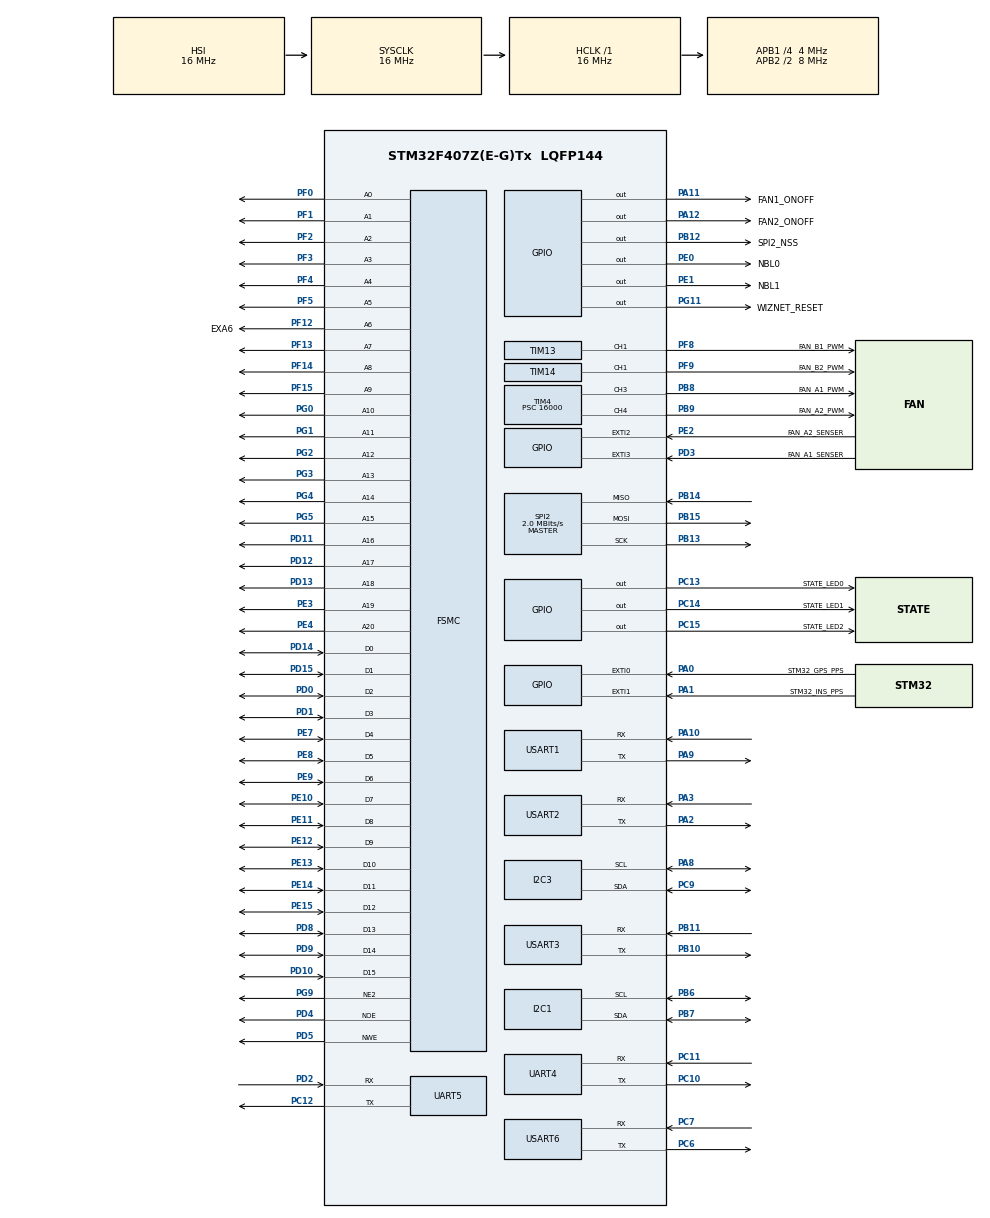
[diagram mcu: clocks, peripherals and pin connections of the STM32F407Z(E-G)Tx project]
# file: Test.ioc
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FSMC.AddressSetupTime2=0
FSMC.BusTurnAroundDuration2=0
FSMC.DataSetupTime2=3
FSMC.WriteOperation2=FSMC_WRITE_OPERATION_ENABLE
Mcu.Family=STM32F4
Mcu.Name=STM32F407Z(E-G)Tx
Mcu.Package=LQFP144
NVIC.PriorityGroup=NVIC_PRIORITYGROUP_4
NVIC.USART2_IRQn=true\:0\:0\:false\:false\:true\:true\:true\:true
PA0-WKUP.GPIO_Label=STM32_GPS_PPS
PA0-WKUP.Signal=GPXTI0
PA1.GPIO_Label=STM32_INS_PPS
PA1.Signal=GPXTI1
PA10.Mode=Asynchronous
PA10.Signal=USART1_RX
PA11.GPIO_Label=FAN1_ONOFF
PA11.Signal=GPIO_Output
PA12.GPIO_Label=FAN2_ONOFF
PA12.Signal=GPIO_Output
PA13.Mode=JTAG_5_pins
PA13.Signal=SYS_JTMS-SWDIO
PA14.Mode=JTAG_5_pins
PA14.Signal=SYS_JTCK-SWCLK
PA15.Mode=JTAG_5_pins
PA15.Signal=SYS_JTDI
PA2.Mode=Asynchronous
PA2.Signal=USART2_TX
PA3.Mode=Asynchronous
PA3.Signal=USART2_RX
PA8.GPIO_Pu=GPIO_PULLUP
PA8.Mode=I2C
PA8.Signal=I2C3_SCL
PA9.Mode=Asynchronous
PA9.Signal=USART1_TX
PB10.Mode=Asynchronous
PB10.Signal=USART3_TX
PB11.Mode=Asynchronous
PB11.Signal=USART3_RX
PB12.GPIO_Label=SPI2_NSS
PB12.Signal=GPIO_Output
PB13.Mode=Full_Duplex_Master
PB13.Signal=SPI2_SCK
PB14.Mode=Full_Duplex_Master
PB14.Signal=SPI2_MISO
PB15.Mode=Full_Duplex_Master
PB15.Signal=SPI2_MOSI
PB3.Mode=JTAG_5_pins
PB3.Signal=SYS_JTDO-SWO
PB4.Mode=JTAG_5_pins
PB4.Signal=SYS_JTRST
PB6.GPIO_Pu=GPIO_PULLUP
PB6.Mode=I2C
PB6.Signal=I2C1_SCL
PB7.GPIO_Pu=GPIO_PULLUP
PB7.Mode=I2C
PB7.Signal=I2C1_SDA
PB8.GPIO_Label=FAN_A1_PWM
PB8.Signal=S_TIM4_CH3
PB9.GPIO_Label=FAN_A2_PWM
PB9.Signal=S_TIM4_CH4
PC10.Mode=Asynchronous
PC10.Signal=UART4_TX
PC11.Mode=Asynchronous
PC11.Signal=UART4_RX
PC12.Mode=Asynchronous
PC12.Signal=UART5_TX
PC13-ANTI_TAMP.GPIO_Label=STATE_LED0
PC13-ANTI_TAMP.Signal=GPIO_Output
PC14-OSC32_IN.GPIO_Label=STATE_LED1
PC14-OSC32_IN.Signal=GPIO_Output
PC15-OSC32_OUT.GPIO_Label=STATE_LED2
PC15-OSC32_OUT.Signal=GPIO_Output
PC6.Mode=Asynchronous
PC6.Signal=USART6_TX
PC7.Mode=Asynchronous
PC7.Signal=USART6_RX
PC9.GPIO_Pu=GPIO_PULLUP
PC9.Mode=I2C
PC9.Signal=I2C3_SDA
PD0.Signal=FSMC_D2_DA2
PD1.Signal=FSMC_D3_DA3
PD10.Signal=FSMC_D15_DA15
PD11.Signal=FSMC_A16_CLE
PD12.Signal=FSMC_A17_ALE
PD13.Signal=FSMC_A18
PD14.Signal=FSMC_D0_DA0
PD15.Signal=FSMC_D1_DA1
PD2.Mode=Asynchronous
PD2.Signal=UART5_RX
PD3.GPIO_Label=FAN_A1_SENSER
PD3.Signal=GPXTI3
PD4.Signal=FSMC_NOE
PD5.Signal=FSMC_NWE
PD8.Signal=FSMC_D13_DA13
PD9.Signal=FSMC_D14_DA14
PE0.GPIO_Label=NBL0
PE0.Signal=GPIO_Output
PE1.GPIO_Label=NBL1
PE1.Signal=GPIO_Output
PE10.Signal=FSMC_D7_DA7
PE11.Signal=FSMC_D8_DA8
PE12.Signal=FSMC_D9_DA9
PE13.Signal=FSMC_D10_DA10
PE14.Signal=FSMC_D11_DA11
PE15.Signal=FSMC_D12_DA12
PE2.GPIO_Label=FAN_A2_SENSER
PE2.Signal=GPXTI2
PE3.Signal=FSMC_A19
PE4.Signal=FSMC_A20
PE7.Signal=FSMC_D4_DA4
PE8.Signal=FSMC_D5_DA5
PE9.Signal=FSMC_D6_DA6
PF0.Signal=FSMC_A0
PF1.Signal=FSMC_A1
PF12.GPIO_Label=EXA6
PF12.Signal=FSMC_A6
PF13.Signal=FSMC_A7
PF14.Signal=FSMC_A8
PF15.Signal=FSMC_A9
PF2.Signal=FSMC_A2
PF3.Signal=FSMC_A3
PF4.Signal=FSMC_A4
PF5.Signal=FSMC_A5
PF8.GPIO_Label=FAN_B1_PWM
PF8.Signal=S_TIM13_CH1
PF9.GPIO_Label=FAN_B2_PWM
PF9.Signal=S_TIM14_CH1
PG0.Signal=FSMC_A10
PG1.Signal=FSMC_A11
PG11.GPIO_Label=WIZNET_RESET
PG11.PinState=GPIO_PIN_SET
PG11.Signal=GPIO_Output
PG2.Signal=FSMC_A12
PG3.Signal=FSMC_A13
PG4.Signal=FSMC_A14
PG5.Signal=FSMC_A15
PG9.Mode=NorPsramChipSelect2_2
PG9.Signal=FSMC_NE2
PH0-OSC_IN.Mode=HSE-External-Oscillator
PH0-OSC_IN.Signal=RCC_OSC_IN
PH1-OSC_OUT.Mode=HSE-External-Oscillator
PH1-OSC_OUT.Signal=RCC_OSC_OUT
ProjectManager.HeapSize=0x200
ProjectManager.StackSize=0x400
ProjectManager.TargetToolchain=EWARM V8.32
RCC.48MHZClocksFreq_Value=32000000
RCC.AHBFreq_Value=16000000
RCC.APB1CLKDivider=RCC_HCLK_DIV4
RCC.APB1Freq_Value=4000000
RCC.APB1TimFreq_Value=8000000
RCC.APB2CLKDivider=RCC_HCLK_DIV2
RCC.APB2Freq_Value=8000000
RCC.APB2TimFreq_Value=16000000
RCC.CortexFreq_Value=16000000
RCC.HCLKFreq_Value=16000000
RCC.HSE_VALUE=25000000
RCC.HSI_VALUE=16000000
RCC.LSE_VALUE=32768
RCC.PLLM=8
RCC.PLLN=64
RCC.SYSCLKFreq_VALUE=16000000
RCC.VCOOutputFreq_Value=128000000
SH.FSMC_A0.0=FSMC_A0,21b-a2
SH.FSMC_A1.0=FSMC_A1,21b-a2
SH.FSMC_A10.0=FSMC_A10,21b-a2
SH.FSMC_A11.0=FSMC_A11,21b-a2
SH.FSMC_A12.0=FSMC_A12,21b-a2
SH.FSMC_A13.0=FSMC_A13,21b-a2
SH.FSMC_A14.0=FSMC_A14,21b-a2
SH.FSMC_A15.0=FSMC_A15,21b-a2
SH.FSMC_A16_CLE.0=FSMC_A16,21b-a2
SH.FSMC_A17_ALE.0=FSMC_A17,21b-a2
SH.FSMC_A18.0=FSMC_A18,21b-a2
SH.FSMC_A19.0=FSMC_A19,21b-a2
SH.FSMC_A2.0=FSMC_A2,21b-a2
SH.FSMC_A20.0=FSMC_A20,21b-a2
SH.FSMC_A3.0=FSMC_A3,21b-a2
SH.FSMC_A4.0=FSMC_A4,21b-a2
SH.FSMC_A5.0=FSMC_A5,21b-a2
SH.FSMC_A6.0=FSMC_A6
SH.FSMC_A6.1=FSMC_A6,21b-a2
SH.FSMC_A7.0=FSMC_A7,21b-a2
SH.FSMC_A8.0=FSMC_A8,21b-a2
SH.FSMC_A9.0=FSMC_A9,21b-a2
SH.FSMC_D0_DA0.0=FSMC_D0,16b-d2
SH.FSMC_D10_DA10.0=FSMC_D10,16b-d2
SH.FSMC_D11_DA11.0=FSMC_D11,16b-d2
SH.FSMC_D12_DA12.0=FSMC_D12,16b-d2
SH.FSMC_D13_DA13.0=FSMC_D13,16b-d2
SH.FSMC_D14_DA14.0=FSMC_D14,16b-d2
SH.FSMC_D15_DA15.0=FSMC_D15,16b-d2
SH.FSMC_D1_DA1.0=FSMC_D1,16b-d2
SH.FSMC_D2_DA2.0=FSMC_D2,16b-d2
SH.FSMC_D3_DA3.0=FSMC_D3,16b-d2
SH.FSMC_D4_DA4.0=FSMC_D4,16b-d2
SH.FSMC_D5_DA5.0=FSMC_D5,16b-d2
SH.FSMC_D6_DA6.0=FSMC_D6,16b-d2
SH.FSMC_D7_DA7.0=FSMC_D7,16b-d2
SH.FSMC_D8_DA8.0=FSMC_D8,16b-d2
SH.FSMC_D9_DA9.0=FSMC_D9,16b-d2
SH.FSMC_NOE.0=FSMC_NOE
SH.FSMC_NOE.1=FSMC_NOE,Sram2
SH.FSMC_NWE.0=FSMC_NWE,Sram2
SH.S_TIM13_CH1.0=TIM13_CH1,PWM Generation1 CH1
SH.S_TIM14_CH1.0=TIM14_CH1,PWM Generation1 CH1
SH.S_TIM4_CH3.0=TIM4_CH3,PWM Generation3 CH3
SH.S_TIM4_CH4.0=TIM4_CH4,PWM Generation4 CH4
SPI2.CalculateBaudRate=2.0 MBits/s
SPI2.Direction=SPI_DIRECTION_2LINES
SPI2.Mode=SPI_MODE_MASTER
SPI2.VirtualType=VM_MASTER
TIM13.Channel=TIM_CHANNEL_1
TIM13.Period=500
TIM13.Prescaler=4000
TIM13.Pulse=350
TIM14.Channel=TIM_CHANNEL_1
TIM14.Period=500
TIM14.Prescaler=4000
TIM14.Pulse=350
TIM4.Channel-PWM\ Generation3\ CH3=TIM_CHANNEL_3
TIM4.Channel-PWM\ Generation4\ CH4=TIM_CHANNEL_4
TIM4.Period=1000
TIM4.Prescaler=16000
TIM4.Pulse-PWM\ Generation3\ CH3=100
TIM4.Pulse-PWM\ Generation4\ CH4=100
UART4.VirtualMode=Asynchronous
UART5.VirtualMode=Asynchronous
USART1.VirtualMode=VM_ASYNC
USART2.VirtualMode=VM_ASYNC
USART3.VirtualMode=VM_ASYNC
USART6.VirtualMode=VM_ASYNC
VP_TIM13_VS_ClockSourceINT.Mode=Enable_Timer
VP_TIM14_VS_ClockSourceINT.Mode=Enable_Timer
VP_TIM4_VS_ClockSourceINT.Mode=Internal
board=custom

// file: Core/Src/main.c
/* USER CODE BEGIN Header */
/**
******************************************************************************
* @file           : main.c
* @brief          : Main program body
******************************************************************************
* @attention
*
* Copyright (c) 2022 STMicroelectronics.
* All rights reserved.
*
* This software is licensed under terms that can be found in the LICENSE file
* in the root directory of this software component.
* If no LICENSE file comes with this software, it is provided AS-IS.
*
******************************************************************************
*/
/* USER CODE END Header */
#include "main.h"

/* USER CODE BEGIN Includes */
#include "stdio.h"
#include "wizchip_conf.h"
/* USER CODE END Includes */

I2C_HandleTypeDef hi2c1;
I2C_HandleTypeDef hi2c3;

SPI_HandleTypeDef hspi2;

TIM_HandleTypeDef htim4;
TIM_HandleTypeDef htim13;
TIM_HandleTypeDef htim14;

UART_HandleTypeDef huart4;
UART_HandleTypeDef huart5;
UART_HandleTypeDef huart1;
UART_HandleTypeDef huart2;
UART_HandleTypeDef huart3;
UART_HandleTypeDef huart6;

SRAM_HandleTypeDef hsram2;

void SystemClock_Config(void);
static void MX_GPIO_Init(void);
static void MX_I2C3_Init(void);
static void MX_UART4_Init(void);
static void MX_UART5_Init(void);
static void MX_USART1_UART_Init(void);
static void MX_USART2_UART_Init(void);
static void MX_USART3_UART_Init(void);
static void MX_USART6_UART_Init(void);
static void MX_SPI2_Init(void);
static void MX_I2C1_Init(void);
static void MX_TIM4_Init(void);
static void MX_FSMC_Init(void);
static void MX_TIM13_Init(void);
static void MX_TIM14_Init(void);

/* USER CODE BEGIN 0 */

#define SOCK_OPEN                       0x01
#define SOCK_CLOSE                      0x10
#define SOCK_MR_UDP                     0x02
#define SOCK_NUM_0                      0x00

#define W5300_BANK_ADDR                 ((uint32_t)0x64000000)
#define _W5300_DATA(p)                  (*(volatile unsigned short*) (W5300_BANK_ADDR + (p<<1)))

uint16_t wr_data;
uint16_t rd_data;

int fputc(int ch,  FILE *f){

  HAL_UART_Transmit(&huart2,(uint8_t*)&ch,1,1);

  return ch;

}
wiz_NetInfo gWIZNETINFO = {
  .mac = {0x00, 0x08, 0xdc, 0, 0, 0},
  .ip = {172, 30, 1, 104},
  .sn = {255, 255, 0, 0},
  .gw = {172, 30, 1, 254},
  .dns = {0, 0, 0, 0},
  .dhcp = NETINFO_STATIC
};
uint8_t wiznet_memsize[2][8] = {{8,8,8,8,8,8,8,8}, {8,8,8,8,8,8,8,8}};
#define ETH_MAX_BUF_SIZE		2048
uint8_t ethBuf0[ETH_MAX_BUF_SIZE];

void Reset_W5300()
{
  HAL_GPIO_WritePin(GPIOG, WIZNET_RESET_Pin, GPIO_PIN_RESET);
  HAL_Delay(1);

  HAL_GPIO_WritePin(GPIOG, WIZNET_RESET_Pin, GPIO_PIN_SET);
  HAL_Delay(10);

}

void W5300_write(uint32_t addr, iodata_t wd)
{
  _W5300_DATA(addr) = wd;
}

iodata_t W5300_read(uint32_t addr)
{
  return _W5300_DATA(addr);
}

void print_network_information(void)
{
  wizchip_getnetinfo(&gWIZNETINFO);
  printf("Mac address: %02x:%02x:%02x:%02x:%02x:%02x\r\n",gWIZNETINFO.mac[0],gWIZNETINFO.mac[1],gWIZNETINFO.mac[2],gWIZNETINFO.mac[3],gWIZNETINFO.mac[4],gWIZNETINFO.mac[5]);
  printf("IP address : %d.%d.%d.%d\r\n",gWIZNETINFO.ip[0],gWIZNETINFO.ip[1],gWIZNETINFO.ip[2],gWIZNETINFO.ip[3]);
  printf("SM Mask    : %d.%d.%d.%d\r\n",gWIZNETINFO.sn[0],gWIZNETINFO.sn[1],gWIZNETINFO.sn[2],gWIZNETINFO.sn[3]);
  printf("Gate way   : %d.%d.%d.%d\r\n",gWIZNETINFO.gw[0],gWIZNETINFO.gw[1],gWIZNETINFO.gw[2],gWIZNETINFO.gw[3]);
  printf("DNS Server : %d.%d.%d.%d\r\n",gWIZNETINFO.dns[0],gWIZNETINFO.dns[1],gWIZNETINFO.dns[2],gWIZNETINFO.dns[3]);
}

void _InitW5300(void)
{
  unsigned int tmpaddr[4];

  Reset_W5300();
  reg_wizchip_bus_cbfunc(W5300_read, W5300_write);

  printf("getMR() = %04X\r\n", getMR());

  if (ctlwizchip(CW_INIT_WIZCHIP, (void*)wiznet_memsize) == -1)
  {
    printf("W5300 memory initialization failed\r\n");
  }

  ctlnetwork(CN_SET_NETINFO, (void *)&gWIZNETINFO);

  print_network_information();
}
/* USER CODE END 0 */

void udp_init(){
  setSn_MR(SOCK_NUM_0,SOCK_MR_UDP);
  setSn_PORT(SOCK_NUM_0,5000);
  setSn_CR(SOCK_NUM_0,SOCK_OPEN);

  //sock open protocols != udp   Close

  if(getSn_SSR(SOCK_NUM_0) !=SOCK_UDP){
    printf("SOCK IS NOT UDP\r\n");
    setSn_CR(SOCK_NUM_0,SOCK_CLOSE);
  }
}
void udp_send_broadcast(){

  uint8_t dip[4]={255,255,255,255};
  uint8_t temp_data[6]={12,34,56,78,90,10};

  /* Set the destination information */
  setSn_DIPR(SOCK_NUM_0,dip);

  setSn_DPORTR(SOCK_NUM_0,5000);

  /* calculate the write count of Sn_TX_FIFOR */
  wiz_send_data(SOCK_NUM_0,temp_data,6);

  setSn_TX_WRSR(SOCK_NUM_0,6);

  setSn_CR(SOCK_NUM_0,Sn_CR_SEND);

}
int main(void)
{

  /* MCU Configuration--------------------------------------------------------*/

  /* Reset of all peripherals, Initializes the Flash interface and the Systick. */
  HAL_Init();

  /* Configure the system clock */
  SystemClock_Config();

  /* Initialize all configured peripherals */
  MX_GPIO_Init();
  MX_I2C3_Init();
  MX_UART4_Init();
  MX_UART5_Init();
  MX_USART1_UART_Init();
  MX_USART2_UART_Init();
  MX_USART3_UART_Init();
  MX_USART6_UART_Init();
  MX_SPI2_Init();
  MX_I2C1_Init();
  MX_TIM4_Init();
  MX_FSMC_Init();
  MX_TIM13_Init();
  MX_TIM14_Init();

  /* Infinite loop */
  /* USER CODE BEGIN WHILE */

  _InitW5300();
  //udp_init();

  while (1)
  {

    /*
    udp_send_broadcast();
    HAL_Delay(1000);
    */
    loopback_tcps(0, ethBuf0, 5000);
    HAL_Delay(1000);

    /*
    rd_data = W5300_read(MR);
    printf("rd_data : %x\r\n",rd_data);
    HAL_Delay(2000);*/

    /* USER CODE END WHILE */

  }
}

void SystemClock_Config(void)
{
  RCC_OscInitTypeDef RCC_OscInitStruct = {0};
  RCC_ClkInitTypeDef RCC_ClkInitStruct = {0};

  /** Configure the main internal regulator output voltage
  */
  __HAL_RCC_PWR_CLK_ENABLE();
  __HAL_PWR_VOLTAGESCALING_CONFIG(PWR_REGULATOR_VOLTAGE_SCALE1);

  /** Initializes the RCC Oscillators according to the specified parameters
  * in the RCC_OscInitTypeDef structure.
  */
  RCC_OscInitStruct.OscillatorType = RCC_OSCILLATORTYPE_HSI;
  RCC_OscInitStruct.HSIState = RCC_HSI_ON;
  RCC_OscInitStruct.HSICalibrationValue = RCC_HSICALIBRATION_DEFAULT;
  RCC_OscInitStruct.PLL.PLLState = RCC_PLL_NONE;
  if (HAL_RCC_OscConfig(&RCC_OscInitStruct) != HAL_OK)
  {
    Error_Handler();
  }

  /** Initializes the CPU, AHB and APB buses clocks
  */
  RCC_ClkInitStruct.ClockType = RCC_CLOCKTYPE_HCLK|RCC_CLOCKTYPE_SYSCLK
    |RCC_CLOCKTYPE_PCLK1|RCC_CLOCKTYPE_PCLK2;
  RCC_ClkInitStruct.SYSCLKSource = RCC_SYSCLKSOURCE_HSI;
  RCC_ClkInitStruct.AHBCLKDivider = RCC_SYSCLK_DIV1;
  RCC_ClkInitStruct.APB1CLKDivider = RCC_HCLK_DIV4;
  RCC_ClkInitStruct.APB2CLKDivider = RCC_HCLK_DIV2;

  if (HAL_RCC_ClockConfig(&RCC_ClkInitStruct, FLASH_LATENCY_0) != HAL_OK)
  {
    Error_Handler();
  }
}

static void MX_I2C1_Init(void)
{

  hi2c1.Instance = I2C1;
  hi2c1.Init.ClockSpeed = 100000;
  hi2c1.Init.DutyCycle = I2C_DUTYCYCLE_2;
  hi2c1.Init.OwnAddress1 = 0;
  hi2c1.Init.AddressingMode = I2C_ADDRESSINGMODE_7BIT;
  hi2c1.Init.DualAddressMode = I2C_DUALADDRESS_DISABLE;
  hi2c1.Init.OwnAddress2 = 0;
  hi2c1.Init.GeneralCallMode = I2C_GENERALCALL_DISABLE;
  hi2c1.Init.NoStretchMode = I2C_NOSTRETCH_DISABLE;
  if (HAL_I2C_Init(&hi2c1) != HAL_OK)
  {
    Error_Handler();
  }

}

static void MX_I2C3_Init(void)
{

  hi2c3.Instance = I2C3;
  hi2c3.Init.ClockSpeed = 100000;
  hi2c3.Init.DutyCycle = I2C_DUTYCYCLE_2;
  hi2c3.Init.OwnAddress1 = 0;
  hi2c3.Init.AddressingMode = I2C_ADDRESSINGMODE_7BIT;
  hi2c3.Init.DualAddressMode = I2C_DUALADDRESS_DISABLE;
  hi2c3.Init.OwnAddress2 = 0;
  hi2c3.Init.GeneralCallMode = I2C_GENERALCALL_DISABLE;
  hi2c3.Init.NoStretchMode = I2C_NOSTRETCH_DISABLE;
  if (HAL_I2C_Init(&hi2c3) != HAL_OK)
  {
    Error_Handler();
  }

}

static void MX_SPI2_Init(void)
{

  /* SPI2 parameter configuration*/
  hspi2.Instance = SPI2;
  hspi2.Init.Mode = SPI_MODE_MASTER;
  hspi2.Init.Direction = SPI_DIRECTION_2LINES;
  hspi2.Init.DataSize = SPI_DATASIZE_8BIT;
  hspi2.Init.CLKPolarity = SPI_POLARITY_LOW;
  hspi2.Init.CLKPhase = SPI_PHASE_1EDGE;
  hspi2.Init.NSS = SPI_NSS_SOFT;
  hspi2.Init.BaudRatePrescaler = SPI_BAUDRATEPRESCALER_2;
  hspi2.Init.FirstBit = SPI_FIRSTBIT_MSB;
  hspi2.Init.TIMode = SPI_TIMODE_DISABLE;
  hspi2.Init.CRCCalculation = SPI_CRCCALCULATION_DISABLE;
  hspi2.Init.CRCPolynomial = 10;
  if (HAL_SPI_Init(&hspi2) != HAL_OK)
  {
    Error_Handler();
  }

}

static void MX_TIM4_Init(void)
{

  TIM_ClockConfigTypeDef sClockSourceConfig = {0};
  TIM_MasterConfigTypeDef sMasterConfig = {0};
  TIM_OC_InitTypeDef sConfigOC = {0};

  htim4.Instance = TIM4;
  htim4.Init.Prescaler = 16000;
  htim4.Init.CounterMode = TIM_COUNTERMODE_UP;
  htim4.Init.Period = 1000;
  htim4.Init.ClockDivision = TIM_CLOCKDIVISION_DIV1;
  htim4.Init.AutoReloadPreload = TIM_AUTORELOAD_PRELOAD_DISABLE;
  if (HAL_TIM_Base_Init(&htim4) != HAL_OK)
  {
    Error_Handler();
  }
  sClockSourceConfig.ClockSource = TIM_CLOCKSOURCE_INTERNAL;
  if (HAL_TIM_ConfigClockSource(&htim4, &sClockSourceConfig) != HAL_OK)
  {
    Error_Handler();
  }
  if (HAL_TIM_PWM_Init(&htim4) != HAL_OK)
  {
    Error_Handler();
  }
  sMasterConfig.MasterOutputTrigger = TIM_TRGO_RESET;
  sMasterConfig.MasterSlaveMode = TIM_MASTERSLAVEMODE_DISABLE;
  if (HAL_TIMEx_MasterConfigSynchronization(&htim4, &sMasterConfig) != HAL_OK)
  {
    Error_Handler();
  }
  sConfigOC.OCMode = TIM_OCMODE_PWM1;
  sConfigOC.Pulse = 100;
  sConfigOC.OCPolarity = TIM_OCPOLARITY_HIGH;
  sConfigOC.OCFastMode = TIM_OCFAST_DISABLE;
  if (HAL_TIM_PWM_ConfigChannel(&htim4, &sConfigOC, TIM_CHANNEL_3) != HAL_OK)
  {
    Error_Handler();
  }
  if (HAL_TIM_PWM_ConfigChannel(&htim4, &sConfigOC, TIM_CHANNEL_4) != HAL_OK)
  {
    Error_Handler();
  }
  HAL_TIM_MspPostInit(&htim4);

}

static void MX_TIM13_Init(void)
{

  TIM_OC_InitTypeDef sConfigOC = {0};

  htim13.Instance = TIM13;
  htim13.Init.Prescaler = 4000;
  htim13.Init.CounterMode = TIM_COUNTERMODE_UP;
  htim13.Init.Period = 500;
  htim13.Init.ClockDivision = TIM_CLOCKDIVISION_DIV1;
  htim13.Init.AutoReloadPreload = TIM_AUTORELOAD_PRELOAD_DISABLE;
  if (HAL_TIM_Base_Init(&htim13) != HAL_OK)
  {
    Error_Handler();
  }
  if (HAL_TIM_PWM_Init(&htim13) != HAL_OK)
  {
    Error_Handler();
  }
  sConfigOC.OCMode = TIM_OCMODE_PWM1;
  sConfigOC.Pulse = 350;
  sConfigOC.OCPolarity = TIM_OCPOLARITY_HIGH;
  sConfigOC.OCFastMode = TIM_OCFAST_DISABLE;
  if (HAL_TIM_PWM_ConfigChannel(&htim13, &sConfigOC, TIM_CHANNEL_1) != HAL_OK)
  {
    Error_Handler();
  }
  HAL_TIM_MspPostInit(&htim13);

}

static void MX_TIM14_Init(void)
{

  TIM_OC_InitTypeDef sConfigOC = {0};

  htim14.Instance = TIM14;
  htim14.Init.Prescaler = 4000;
  htim14.Init.CounterMode = TIM_COUNTERMODE_UP;
  htim14.Init.Period = 500;
  htim14.Init.ClockDivision = TIM_CLOCKDIVISION_DIV1;
  htim14.Init.AutoReloadPreload = TIM_AUTORELOAD_PRELOAD_DISABLE;
  if (HAL_TIM_Base_Init(&htim14) != HAL_OK)
  {
    Error_Handler();
  }
  if (HAL_TIM_PWM_Init(&htim14) != HAL_OK)
  {
    Error_Handler();
  }
  sConfigOC.OCMode = TIM_OCMODE_PWM1;
  sConfigOC.Pulse = 350;
  sConfigOC.OCPolarity = TIM_OCPOLARITY_HIGH;
  sConfigOC.OCFastMode = TIM_OCFAST_DISABLE;
  if (HAL_TIM_PWM_ConfigChannel(&htim14, &sConfigOC, TIM_CHANNEL_1) != HAL_OK)
  {
    Error_Handler();
  }
  HAL_TIM_MspPostInit(&htim14);

}

static void MX_UART4_Init(void)
{

  huart4.Instance = UART4;
  huart4.Init.BaudRate = 115200;
  huart4.Init.WordLength = UART_WORDLENGTH_8B;
  huart4.Init.StopBits = UART_STOPBITS_1;
  huart4.Init.Parity = UART_PARITY_NONE;
  huart4.Init.Mode = UART_MODE_TX_RX;
  huart4.Init.HwFlowCtl = UART_HWCONTROL_NONE;
  huart4.Init.OverSampling = UART_OVERSAMPLING_16;
  if (HAL_UART_Init(&huart4) != HAL_OK)
  {
    Error_Handler();
  }

}

static void MX_UART5_Init(void)
{

  huart5.Instance = UART5;
  huart5.Init.BaudRate = 115200;
  huart5.Init.WordLength = UART_WORDLENGTH_8B;
  huart5.Init.StopBits = UART_STOPBITS_1;
  huart5.Init.Parity = UART_PARITY_NONE;
  huart5.Init.Mode = UART_MODE_TX_RX;
  huart5.Init.HwFlowCtl = UART_HWCONTROL_NONE;
  huart5.Init.OverSampling = UART_OVERSAMPLING_16;
  if (HAL_UART_Init(&huart5) != HAL_OK)
  {
    Error_Handler();
  }

}

static void MX_USART1_UART_Init(void)
{

  huart1.Instance = USART1;
  huart1.Init.BaudRate = 115200;
  huart1.Init.WordLength = UART_WORDLENGTH_8B;
  huart1.Init.StopBits = UART_STOPBITS_1;
  huart1.Init.Parity = UART_PARITY_NONE;
  huart1.Init.Mode = UART_MODE_TX_RX;
  huart1.Init.HwFlowCtl = UART_HWCONTROL_NONE;
  huart1.Init.OverSampling = UART_OVERSAMPLING_16;
  if (HAL_UART_Init(&huart1) != HAL_OK)
  {
    Error_Handler();
  }

}

static void MX_USART2_UART_Init(void)
{

  huart2.Instance = USART2;
  huart2.Init.BaudRate = 115200;
  huart2.Init.WordLength = UART_WORDLENGTH_8B;
  huart2.Init.StopBits = UART_STOPBITS_1;
  huart2.Init.Parity = UART_PARITY_NONE;
  huart2.Init.Mode = UART_MODE_TX_RX;
  huart2.Init.HwFlowCtl = UART_HWCONTROL_NONE;
  huart2.Init.OverSampling = UART_OVERSAMPLING_16;
  if (HAL_UART_Init(&huart2) != HAL_OK)
  {
    Error_Handler();
  }

}

static void MX_USART3_UART_Init(void)
{

  huart3.Instance = USART3;
  huart3.Init.BaudRate = 115200;
  huart3.Init.WordLength = UART_WORDLENGTH_8B;
  huart3.Init.StopBits = UART_STOPBITS_1;
  huart3.Init.Parity = UART_PARITY_NONE;
  huart3.Init.Mode = UART_MODE_TX_RX;
  huart3.Init.HwFlowCtl = UART_HWCONTROL_NONE;
  huart3.Init.OverSampling = UART_OVERSAMPLING_16;
  if (HAL_UART_Init(&huart3) != HAL_OK)
  {
    Error_Handler();
  }

}

static void MX_USART6_UART_Init(void)
{

  huart6.Instance = USART6;
  huart6.Init.BaudRate = 115200;
  huart6.Init.WordLength = UART_WORDLENGTH_8B;
  huart6.Init.StopBits = UART_STOPBITS_1;
  huart6.Init.Parity = UART_PARITY_NONE;
  huart6.Init.Mode = UART_MODE_TX_RX;
  huart6.Init.HwFlowCtl = UART_HWCONTROL_NONE;
  huart6.Init.OverSampling = UART_OVERSAMPLING_16;
  if (HAL_UART_Init(&huart6) != HAL_OK)
  {
    Error_Handler();
  }

}

static void MX_GPIO_Init(void)
{
  GPIO_InitTypeDef GPIO_InitStruct = {0};

  /* GPIO Ports Clock Enable */
  __HAL_RCC_GPIOE_CLK_ENABLE();
  __HAL_RCC_GPIOC_CLK_ENABLE();
  __HAL_RCC_GPIOF_CLK_ENABLE();
  __HAL_RCC_GPIOH_CLK_ENABLE();
  __HAL_RCC_GPIOA_CLK_ENABLE();
  __HAL_RCC_GPIOG_CLK_ENABLE();
  __HAL_RCC_GPIOB_CLK_ENABLE();
  __HAL_RCC_GPIOD_CLK_ENABLE();

  /*Configure GPIO pin Output Level */
  HAL_GPIO_WritePin(GPIOC, STATE_LED0_Pin|STATE_LED1_Pin|STATE_LED2_Pin, GPIO_PIN_RESET);

  /*Configure GPIO pin Output Level */
  HAL_GPIO_WritePin(SPI2_NSS_GPIO_Port, SPI2_NSS_Pin, GPIO_PIN_RESET);

  /*Configure GPIO pin Output Level */
  HAL_GPIO_WritePin(GPIOA, FAN1_ONOFF_Pin|FAN2_ONOFF_Pin, GPIO_PIN_RESET);

  /*Configure GPIO pin Output Level */
  HAL_GPIO_WritePin(WIZNET_RESET_GPIO_Port, WIZNET_RESET_Pin, GPIO_PIN_SET);

  /*Configure GPIO pin Output Level */
  HAL_GPIO_WritePin(GPIOE, NBL0_Pin|NBL1_Pin, GPIO_PIN_RESET);

  /*Configure GPIO pin : FAN_A2_SENSER_Pin */
  GPIO_InitStruct.Pin = FAN_A2_SENSER_Pin;
  GPIO_InitStruct.Mode = GPIO_MODE_IT_RISING;
  GPIO_InitStruct.Pull = GPIO_NOPULL;
  HAL_GPIO_Init(FAN_A2_SENSER_GPIO_Port, &GPIO_InitStruct);

  /*Configure GPIO pins : STATE_LED0_Pin STATE_LED1_Pin STATE_LED2_Pin */
  GPIO_InitStruct.Pin = STATE_LED0_Pin|STATE_LED1_Pin|STATE_LED2_Pin;
  GPIO_InitStruct.Mode = GPIO_MODE_OUTPUT_PP;
  GPIO_InitStruct.Pull = GPIO_NOPULL;
  GPIO_InitStruct.Speed = GPIO_SPEED_FREQ_LOW;
  HAL_GPIO_Init(GPIOC, &GPIO_InitStruct);

  /*Configure GPIO pins : STM32_GPS_PPS_Pin STM32_INS_PPS_Pin */
  GPIO_InitStruct.Pin = STM32_GPS_PPS_Pin|STM32_INS_PPS_Pin;
  GPIO_InitStruct.Mode = GPIO_MODE_IT_RISING;
  GPIO_InitStruct.Pull = GPIO_NOPULL;
  HAL_GPIO_Init(GPIOA, &GPIO_InitStruct);

  /*Configure GPIO pin : SPI2_NSS_Pin */
  GPIO_InitStruct.Pin = SPI2_NSS_Pin;
  GPIO_InitStruct.Mode = GPIO_MODE_OUTPUT_PP;
  GPIO_InitStruct.Pull = GPIO_NOPULL;
  GPIO_InitStruct.Speed = GPIO_SPEED_FREQ_LOW;
  HAL_GPIO_Init(SPI2_NSS_GPIO_Port, &GPIO_InitStruct);

  /*Configure GPIO pins : FAN1_ONOFF_Pin FAN2_ONOFF_Pin */
  GPIO_InitStruct.Pin = FAN1_ONOFF_Pin|FAN2_ONOFF_Pin;
  GPIO_InitStruct.Mode = GPIO_MODE_OUTPUT_PP;
  GPIO_InitStruct.Pull = GPIO_NOPULL;
  GPIO_InitStruct.Speed = GPIO_SPEED_FREQ_LOW;
  HAL_GPIO_Init(GPIOA, &GPIO_InitStruct);

  /*Configure GPIO pin : FAN_A1_SENSER_Pin */
  GPIO_InitStruct.Pin = FAN_A1_SENSER_Pin;
  GPIO_InitStruct.Mode = GPIO_MODE_IT_RISING;
  GPIO_InitStruct.Pull = GPIO_NOPULL;
  HAL_GPIO_Init(FAN_A1_SENSER_GPIO_Port, &GPIO_InitStruct);

  /*Configure GPIO pin : WIZNET_RESET_Pin */
  GPIO_InitStruct.Pin = WIZNET_RESET_Pin;
  GPIO_InitStruct.Mode = GPIO_MODE_OUTPUT_PP;
  GPIO_InitStruct.Pull = GPIO_NOPULL;
  GPIO_InitStruct.Speed = GPIO_SPEED_FREQ_LOW;
  HAL_GPIO_Init(WIZNET_RESET_GPIO_Port, &GPIO_InitStruct);

  /*Configure GPIO pins : NBL0_Pin NBL1_Pin */
  GPIO_InitStruct.Pin = NBL0_Pin|NBL1_Pin;
  GPIO_InitStruct.Mode = GPIO_MODE_OUTPUT_PP;
  GPIO_InitStruct.Pull = GPIO_NOPULL;
  GPIO_InitStruct.Speed = GPIO_SPEED_FREQ_LOW;
  HAL_GPIO_Init(GPIOE, &GPIO_InitStruct);

}

/* FSMC initialization function */
static void MX_FSMC_Init(void)
{

  FSMC_NORSRAM_TimingTypeDef Timing = {0};

  /** Perform the SRAM2 memory initialization sequence
  */
  hsram2.Instance = FSMC_NORSRAM_DEVICE;
  hsram2.Extended = FSMC_NORSRAM_EXTENDED_DEVICE;
  /* hsram2.Init */
  hsram2.Init.NSBank = FSMC_NORSRAM_BANK2;
  hsram2.Init.DataAddressMux = FSMC_DATA_ADDRESS_MUX_DISABLE;
  hsram2.Init.MemoryType = FSMC_MEMORY_TYPE_SRAM;
  hsram2.Init.MemoryDataWidth = FSMC_NORSRAM_MEM_BUS_WIDTH_16;
  hsram2.Init.BurstAccessMode = FSMC_BURST_ACCESS_MODE_DISABLE;
  hsram2.Init.WaitSignalPolarity = FSMC_WAIT_SIGNAL_POLARITY_LOW;
  hsram2.Init.WrapMode = FSMC_WRAP_MODE_DISABLE;
  hsram2.Init.WaitSignalActive = FSMC_WAIT_TIMING_BEFORE_WS;
  hsram2.Init.WriteOperation = FSMC_WRITE_OPERATION_ENABLE;
  hsram2.Init.WaitSignal = FSMC_WAIT_SIGNAL_DISABLE;
  hsram2.Init.ExtendedMode = FSMC_EXTENDED_MODE_DISABLE;
  hsram2.Init.AsynchronousWait = FSMC_ASYNCHRONOUS_WAIT_DISABLE;
  hsram2.Init.WriteBurst = FSMC_WRITE_BURST_DISABLE;
  hsram2.Init.PageSize = FSMC_PAGE_SIZE_NONE;
  /* Timing */
  Timing.AddressSetupTime = 0;
  Timing.AddressHoldTime = 15;
  Timing.DataSetupTime = 3;
  Timing.BusTurnAroundDuration = 0;
  Timing.CLKDivision = 16;
  Timing.DataLatency = 17;
  Timing.AccessMode = FSMC_ACCESS_MODE_A;
  /* ExtTiming */

  if (HAL_SRAM_Init(&hsram2, &Timing, NULL) != HAL_OK)
  {
    Error_Handler( );
  }

}

void Error_Handler(void)
{
  __disable_irq();
  while (1)
  {
  }
}
